# CY8C5287AXI_LP095 register map
File version: 0.1
Registers are 8-bit, read-write, no defined reset value unless marked. A register's access mark holds for its fields unless they carry their own. Offsets are from the block's base; [hi:lo] are bit positions; {n}, {i} and the like mark numbered series.

## SIM800L_SIM_REG
Base 0x00000000
0x40006470 SIM800L_SIM_REG_CONTROL_REG

## SIM800L_SIM — UART
Base 0x00000000
0x40006423 RX_SIM800L_SIM_RX_ADDRESS1 — RX Address1 Register
0x40006433 RX_SIM800L_SIM_RX_ADDRESS2 — RX Address2 Register
0x40006443 RX_SIM800L_SIM_RX_DATA — RX Data Register
0x4000644D TX_SIM800L_SIM_TX_DATA — TX Data Register
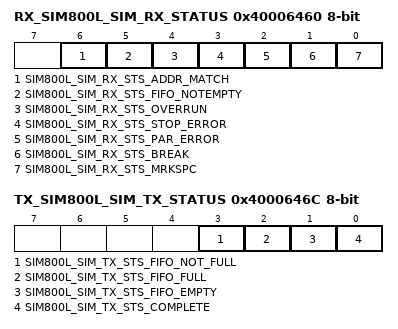
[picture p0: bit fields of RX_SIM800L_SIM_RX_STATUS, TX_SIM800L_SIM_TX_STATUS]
0x40006460 RX_SIM800L_SIM_RX_STATUS — RX status register
  [6] SIM800L_SIM_RX_STS_ADDR_MATCH ro, [5] SIM800L_SIM_RX_STS_FIFO_NOTEMPTY ro, [4] SIM800L_SIM_RX_STS_OVERRUN ro, [3] SIM800L_SIM_RX_STS_STOP_ERROR ro, [2] SIM800L_SIM_RX_STS_PAR_ERROR ro, [1] SIM800L_SIM_RX_STS_BREAK ro, [0] SIM800L_SIM_RX_STS_MRKSPC ro
0x4000646C TX_SIM800L_SIM_TX_STATUS — TX status register
  [3] SIM800L_SIM_TX_STS_FIFO_NOT_FULL ro, [2] SIM800L_SIM_TX_STS_FIFO_FULL ro, [1] SIM800L_SIM_TX_STS_FIFO_EMPTY ro, [0] SIM800L_SIM_TX_STS_COMPLETE ro

## RTC_RTC — RTC
Base 0x00000000
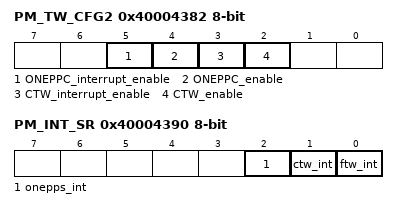
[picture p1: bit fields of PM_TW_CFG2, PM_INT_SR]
0x40004382 PM_TW_CFG2 — Power timers enable and interrupt enable configuration register
  [5] ONEPPC_interrupt_enable — When set and one pulse-per-second is enabled, an interrupt is issued when the pulse occurs
    1=Enabled (The ONEPPC interrupt is issued. Only if ONEPPC is enabled.); 0=Disabled (No ONEPPC interrupt is issued.)
  [4] ONEPPC_enable
    1=Enabled (The ONEPPC is enabled.); 0=Disabled (The ONEPPC is disabled.)
  [3] CTW_interrupt_enable — An interrupt issue when the CTW reaches the selected interval
    1=Enabled (The CTW interrupt is issued. Only if CTW is enabled.); 0=Disabled (No CTW interrupt is issued.)
  [2] CTW_enable
    1=Enabled (The CTW is enabled.); 0=Disabled (The CTW is disabled.)
0x40004390 PM_INT_SR — Power Manager Interrupt Status Register
  [2] onepps_int — When set, a onepps event has occured.
  [1] ctw_int — When set, a limited active ready event has occured
  [0] ftw_int — When set, a fast timewheel event has occured

## MDB_UART — UART
Base 0x00000000
0x4000642B RX_MDB_UART_RX_ADDRESS1 — RX Address1 Register
0x4000643B RX_MDB_UART_RX_ADDRESS2 — RX Address2 Register
0x4000644B RX_MDB_UART_RX_DATA — RX Data Register
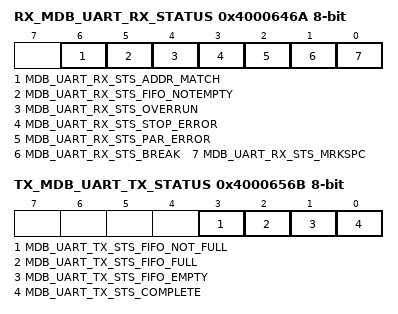
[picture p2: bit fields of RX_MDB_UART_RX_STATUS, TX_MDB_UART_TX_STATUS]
0x4000646A RX_MDB_UART_RX_STATUS — RX status register
  [6] MDB_UART_RX_STS_ADDR_MATCH ro, [5] MDB_UART_RX_STS_FIFO_NOTEMPTY ro, [4] MDB_UART_RX_STS_OVERRUN ro, [3] MDB_UART_RX_STS_STOP_ERROR ro, [2] MDB_UART_RX_STS_PAR_ERROR ro, [1] MDB_UART_RX_STS_BREAK ro, [0] MDB_UART_RX_STS_MRKSPC ro
0x4000654B TX_MDB_UART_TX_DATA — TX Data Register
0x4000656B TX_MDB_UART_TX_STATUS — TX status register
  [3] MDB_UART_TX_STS_FIFO_NOT_FULL ro, [2] MDB_UART_TX_STS_FIFO_FULL ro, [1] MDB_UART_TX_STS_FIFO_EMPTY ro, [0] MDB_UART_TX_STS_COMPLETE ro

## PWM_Led
Base 0x00000000
0x400043A3 PWM_Led_GLOBAL_ENABLE — PM.ACT.CFG
  [3:0] en_timer — Enable timer/counters.
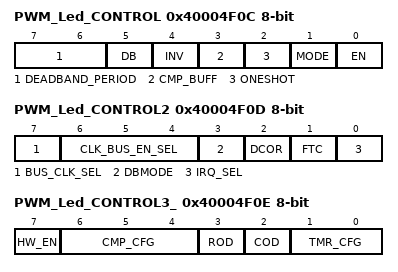
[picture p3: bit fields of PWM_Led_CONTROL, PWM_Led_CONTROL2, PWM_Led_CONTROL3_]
0x40004F0C PWM_Led_CONTROL — TMRx.CFG0
  [7:6] DEADBAND_PERIOD
  [5] DB — Deadband mode--Deadband phases phi1 and phi2 are outputted on CMP and TC output pins respectively.
    0=Timer (CMP and TC are output.); 1=Deadband (PHI1 (instead of CMP) and PHI2 (instead of TC) are output.)
  [4] INV — Invert sense of TIMEREN signal
  [3] CMP_BUFF — Buffer compare register. Compare register updates only on timer terminal count.
  [2] ONESHOT — Timer stops upon reaching stop condition defined by TMR_CFG bits. Can be restarted by asserting TIMER RESET or disabling and re-enabling block.
  [1] MODE — Mode. (0 = Timer; 1 = Comparator)
    0=Timer mode. CNT/CMP register holds timer count value.; 1=Comparator mode. CNT/CMP register holds comparator threshold value.
  [0] EN — Enables timer/comparator.
0x40004F0D PWM_Led_CONTROL2 — TMRx.CFG1
  [7] BUS_CLK_SEL — Bus Clock selection.
  [6:4] CLK_BUS_EN_SEL — Digital Global Clock selection.
  [3] DBMODE — Deadband mode (asynchronous/synchronous). CMP output pin is also affected when not in deadband mode (CFG0.DEADBAND).
  [2] DCOR — Disable Clear on Read (DCOR) of Status Register SR0.
  [1] FTC — First Terminal Count (FTC). Setting this bit forces a single pulse on the TC pin when first enabled.
    0=Disable_FTC (Disable the single cycle pulse, which signifies the timer is starting.); 1=Enable_FTC (Enable the single cycle pulse, which signifies the timer is starting.)
  [0] IRQ_SEL — Irq selection. (0 = raw interrupts; 1 = status register interrupts)
0x40004F0E PWM_Led_CONTROL3_ — TMRx.CFG2
  [7] HW_EN — When set Timer Enable controls counting.
  [6:4] CMP_CFG — Comparator configurations
    0=Equal (Compare Equal); 1=Less_than (Compare Less Than); 2=Less_than_or_equal (Compare Less Than or Equal .); 3=Greater (Compare Greater Than .); 4=Greater_than_or_equal (Compare Greater Than or Equal)
  [3] ROD — Reset On Disable (ROD). Resets internal state of output logic
  [2] COD — Clear On Disable (COD). Clears or gates outputs to zero.
  [1:0] TMR_CFG — Timer configuration (MODE = 0): 000 = Continuous; 001 = Pulsewidth; 010 = Period; 011 = Stop on IRQ
    0=Continuous (Timer runs while EN bit of CFG0 register is set to '1'.); 1=Pulsewidth (Timer runs from positive to negative edge of TIMEREN.); 2=Period (Timer runs from positive to positive edge of TIMEREN.); 3=Irq (Timer runs until IRQ.)
0x40004F10 PWM_Led_PERIOD — TMRx.PER0 - Assigned Period
0x40004F12 PWM_Led_COMPARE — TMRx.CNT_CMP0 - Assigned Compare Value

## ADC_Vending — SAR ADC
Base 0x00000000
0x40004614 SAR_TR0 — SAR trim register
{0x40005900+i} SAR_CSR{i} (i=0..6) — SAR status and control register {i}
0x40005B20 SAR_SW0 — SAR Analog Routing Register 0
{0x40005B20+i} SAR_SW{i} (i=2..4) — SAR Analog Routing Register {i}
0x40005B26 SAR_SW6 — SAR Analog Routing Register 6
0x40005B27 SAR_CLK — SAR Clock Selection Register
0x40005BA0 SAR_WRK 16-bit — SAR working register

## FINGER — UART
Base 0x00000000
0x40006429 RX_FINGER_RX_ADDRESS1 — RX Address1 Register
0x40006439 RX_FINGER_RX_ADDRESS2 — RX Address2 Register
0x40006449 RX_FINGER_RX_DATA — RX Data Register
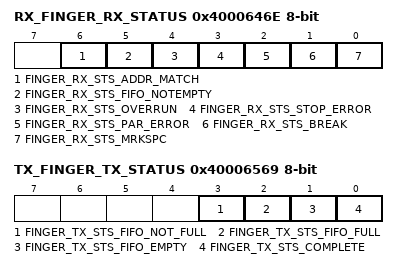
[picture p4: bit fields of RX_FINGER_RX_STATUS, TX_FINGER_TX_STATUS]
0x4000646E RX_FINGER_RX_STATUS — RX status register
  [6] FINGER_RX_STS_ADDR_MATCH ro, [5] FINGER_RX_STS_FIFO_NOTEMPTY ro, [4] FINGER_RX_STS_OVERRUN ro, [3] FINGER_RX_STS_STOP_ERROR ro, [2] FINGER_RX_STS_PAR_ERROR ro, [1] FINGER_RX_STS_BREAK ro, [0] FINGER_RX_STS_MRKSPC ro
0x40006549 TX_FINGER_TX_DATA — TX Data Register
0x40006569 TX_FINGER_TX_STATUS — TX status register
  [3] FINGER_TX_STS_FIFO_NOT_FULL ro, [2] FINGER_TX_STS_FIFO_FULL ro, [1] FINGER_TX_STS_FIFO_EMPTY ro, [0] FINGER_TX_STS_COMPLETE ro
